# DDR32SS0_CTLPHY_WRAP_CTL_CFG_CTLCFG register map
Vendor: Texas Instruments
Registers are 32-bit, read-write, reset 0x0 unless marked. A register's access mark holds for its fields unless they carry their own. Offsets are as the file gives them; [hi:lo] are bit positions; {n}, {i} and the like mark numbered series.

## DDR32SS0_CTLPHY_WRAP_CTL_CFG_CTLCFG (part 10 of 11)
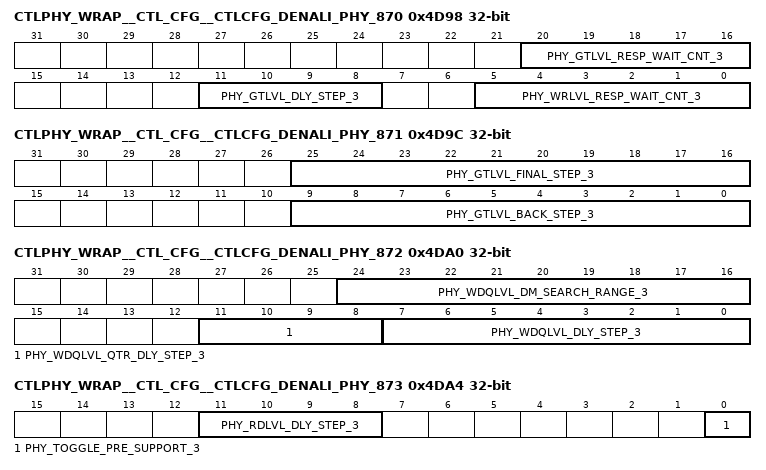
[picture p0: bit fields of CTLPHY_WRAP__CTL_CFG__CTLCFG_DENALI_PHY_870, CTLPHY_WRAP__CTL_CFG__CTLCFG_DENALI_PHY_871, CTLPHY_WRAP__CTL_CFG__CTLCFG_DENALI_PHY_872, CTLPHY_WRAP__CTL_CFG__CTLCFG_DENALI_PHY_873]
0x4D98 CTLPHY_WRAP__CTL_CFG__CTLCFG_DENALI_PHY_870
  [20:16] PHY_GTLVL_RESP_WAIT_CNT_3 — Number of cycles + 4 to wait between dfi_rddata_en and the sampling of the DQS during gate training for slice 3. The valid range is 0x0 to 0xB.
  [11:8] PHY_GTLVL_DLY_STEP_3 — DQS target delay step size during gate training for slice 3.
  [5:0] PHY_WRLVL_RESP_WAIT_CNT_3 — Number of cycles to wait between dfi_wrlvl_strobe and the sampling of the DQs during write leveling for slice 3.
0x4D9C CTLPHY_WRAP__CTL_CFG__CTLCFG_DENALI_PHY_871
  [25:16] PHY_GTLVL_FINAL_STEP_3 — Final backup step delay used in gate training algorithm for slice 3.
  [9:0] PHY_GTLVL_BACK_STEP_3 — Interim backup step delay used in gate training algorithm for slice 3.
0x4DA0 CTLPHY_WRAP__CTL_CFG__CTLCFG_DENALI_PHY_872
  [24:16] PHY_WDQLVL_DM_SEARCH_RANGE_3 — The dm target delay search range for non-lpddr4 DM training for slice 3.
  [11:8] PHY_WDQLVL_QTR_DLY_STEP_3 — Defines the step granularity for the logic to use once an edge is found for slice 3. When this occurs, the logic jumps back to the previous invalid value and uses this step size to determine a more accurate delay value.
  [7:0] PHY_WDQLVL_DLY_STEP_3 — DQ target delay step size during write data leveling for slice 3.
0x4DA4 CTLPHY_WRAP__CTL_CFG__CTLCFG_DENALI_PHY_873
  [11:8] PHY_RDLVL_DLY_STEP_3 — DQS target delay step size during read leveling for slice 3.
  [0] PHY_TOGGLE_PRE_SUPPORT_3 — Support the toggle read preamble for LPDDR4 for slice 3.
0x4DA8 CTLPHY_WRAP__CTL_CFG__CTLCFG_DENALI_PHY_874
  [9:0] PHY_RDLVL_MAX_EDGE_3 — The maximun rdlvl target delay search window for read eye training for slice 3.
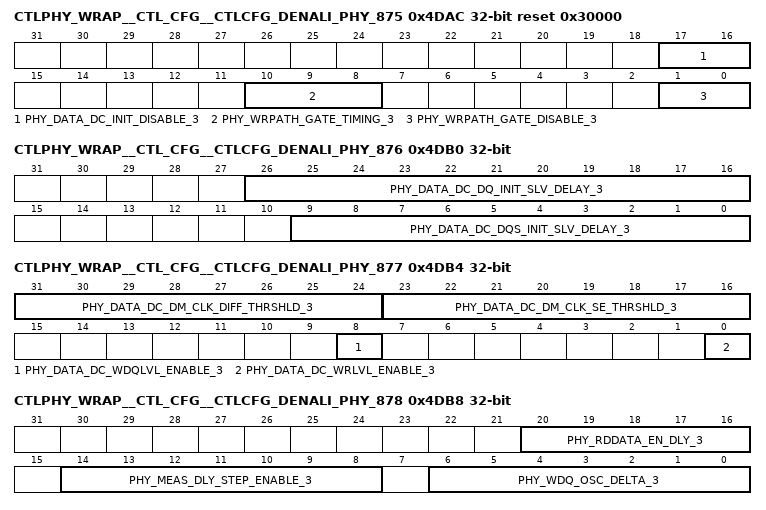
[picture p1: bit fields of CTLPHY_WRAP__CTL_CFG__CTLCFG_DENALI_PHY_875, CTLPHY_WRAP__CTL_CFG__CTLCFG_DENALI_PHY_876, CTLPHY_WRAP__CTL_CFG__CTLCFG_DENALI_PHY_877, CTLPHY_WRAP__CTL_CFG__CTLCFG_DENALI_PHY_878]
0x4DAC CTLPHY_WRAP__CTL_CFG__CTLCFG_DENALI_PHY_875 reset 0x30000
  [17:16] PHY_DATA_DC_INIT_DISABLE_3 — Disable duty cycle adjust at initialization for slice 3.
  [10:8] PHY_WRPATH_GATE_TIMING_3 — Write path clock gating timing for slice 3. it means additional clock number to write path clock gate
  [1:0] PHY_WRPATH_GATE_DISABLE_3 — Write path clock gating disable for slice 3. [0]: disable pull in wrdata_en; [1]: disable write path clock gating, clock always on
0x4DB0 CTLPHY_WRAP__CTL_CFG__CTLCFG_DENALI_PHY_876
  [26:16] PHY_DATA_DC_DQ_INIT_SLV_DELAY_3 — Initial value of write DQ target delay for slice 3.
  [9:0] PHY_DATA_DC_DQS_INIT_SLV_DELAY_3 — Initial value of write DQS target delay for slice 3.
0x4DB4 CTLPHY_WRAP__CTL_CFG__CTLCFG_DENALI_PHY_877
  [31:24] PHY_DATA_DC_DM_CLK_DIFF_THRSHLD_3 — Clock measurement cell threshold offset for differential signals for slice 3.
  [23:16] PHY_DATA_DC_DM_CLK_SE_THRSHLD_3 — Clock measurement cell threshold offset for single ended signals for slice 3.
  [8] PHY_DATA_DC_WDQLVL_ENABLE_3 — Enable duty cycle adjust during write DQ training for slice 3.
  [0] PHY_DATA_DC_WRLVL_ENABLE_3 — Enable duty cycle adjust during write leveling for slice 3.
0x4DB8 CTLPHY_WRAP__CTL_CFG__CTLCFG_DENALI_PHY_878
  [20:16] PHY_RDDATA_EN_DLY_3 — Number of cycles that the dfi_rddata_en signal is early for slice 3.
  [14:8] PHY_MEAS_DLY_STEP_ENABLE_3 — Data slice training step definition using phy_meas_dly_step_value for slice 3.
  [6:0] PHY_WDQ_OSC_DELTA_3 — Target delay offset that applies to a 1 bit change of dfi_wdq_osc_code for slice 3.
0x4DBC CTLPHY_WRAP__CTL_CFG__CTLCFG_DENALI_PHY_879
  [31:0] PHY_DQ_DM_SWIZZLE0_3 — DQ/DM bit swizzling 0 for slice 3. Bits [3:0] inform the PHY which bit in {DM,DQ]} map to DQ0, Bits [7:4] inform the PHY which bit in {DM,DQ} map to DQ1, etc.
0x4DC0 CTLPHY_WRAP__CTL_CFG__CTLCFG_DENALI_PHY_880
  [3:0] PHY_DQ_DM_SWIZZLE1_3 — DQ/DM bit swizzling 1 for slice 3. Bits [3:0] inform the PHY which bit in {DM,DQ]} map to DM.
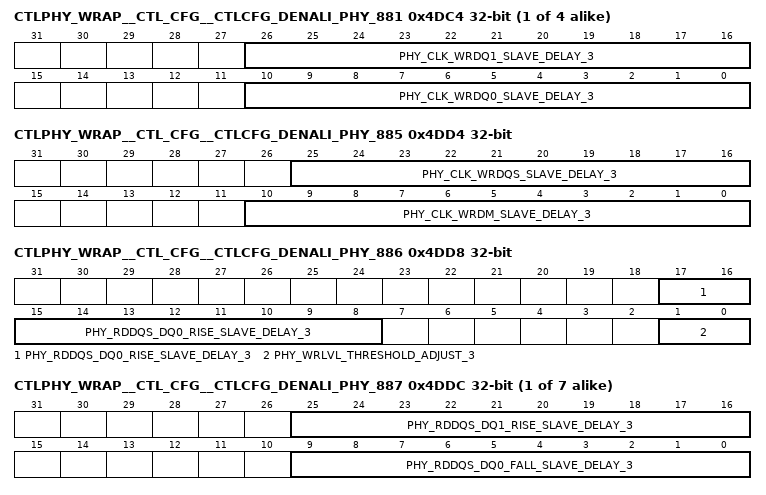
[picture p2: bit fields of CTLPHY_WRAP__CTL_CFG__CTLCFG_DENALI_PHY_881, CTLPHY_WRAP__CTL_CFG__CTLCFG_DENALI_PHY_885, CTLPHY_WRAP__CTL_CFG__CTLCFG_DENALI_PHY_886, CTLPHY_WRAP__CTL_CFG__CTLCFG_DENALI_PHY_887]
{0x4000+4i} CTLPHY_WRAP__CTL_CFG__CTLCFG_DENALI_PHY_{i} (i=881..884)
  [26:16] PHY_CLK_WRDQ{2i-1761}_SLAVE_DELAY_3 — Write clock target delay setting for DQ{2i-1761} for slice 3.
  [10:0] PHY_CLK_WRDQ{2i-1762}_SLAVE_DELAY_3 — Write clock target delay setting for DQ{2i-1762} for slice 3.
0x4DD4 CTLPHY_WRAP__CTL_CFG__CTLCFG_DENALI_PHY_885
  [25:16] PHY_CLK_WRDQS_SLAVE_DELAY_3 — Write clock target delay setting for DQS for slice 3.
  [10:0] PHY_CLK_WRDM_SLAVE_DELAY_3 — Write clock target delay setting for DM for slice 3.
0x4DD8 CTLPHY_WRAP__CTL_CFG__CTLCFG_DENALI_PHY_886
  [17:8] PHY_RDDQS_DQ0_RISE_SLAVE_DELAY_3 — Rising edge read DQS target delay setting for DQ0 for slice 3.
  [1:0] PHY_WRLVL_THRESHOLD_ADJUST_3 — Write level threshold adjust value based on those thresholds for DQS for slice 3.
{0x4000+4i} CTLPHY_WRAP__CTL_CFG__CTLCFG_DENALI_PHY_{i} (i=887..893)
  [25:16] PHY_RDDQS_DQ{i-886}_RISE_SLAVE_DELAY_3 — Rising edge read DQS target delay setting for DQ{i-886} for slice 3.
  [9:0] PHY_RDDQS_DQ{i-887}_FALL_SLAVE_DELAY_3 — Falling edge read DQS target delay setting for DQ{i-887} for slice 3.
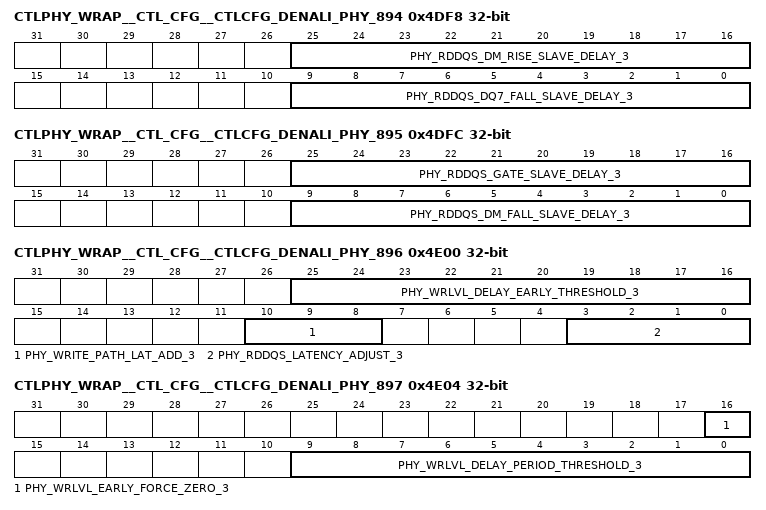
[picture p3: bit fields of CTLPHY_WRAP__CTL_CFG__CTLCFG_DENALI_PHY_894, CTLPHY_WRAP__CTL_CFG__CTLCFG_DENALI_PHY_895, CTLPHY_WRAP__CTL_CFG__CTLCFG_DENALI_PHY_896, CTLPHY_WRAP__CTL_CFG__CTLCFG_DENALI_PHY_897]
0x4DF8 CTLPHY_WRAP__CTL_CFG__CTLCFG_DENALI_PHY_894
  [25:16] PHY_RDDQS_DM_RISE_SLAVE_DELAY_3 — Rising edge read DQS target delay setting for DM for slice 3.
  [9:0] PHY_RDDQS_DQ7_FALL_SLAVE_DELAY_3 — Falling edge read DQS target delay setting for DQ7 for slice 3.
0x4DFC CTLPHY_WRAP__CTL_CFG__CTLCFG_DENALI_PHY_895
  [25:16] PHY_RDDQS_GATE_SLAVE_DELAY_3 — Read DQS target delay setting for slice 3.
  [9:0] PHY_RDDQS_DM_FALL_SLAVE_DELAY_3 — Falling edge read DQS target delay setting for DM for slice 3.
0x4E00 CTLPHY_WRAP__CTL_CFG__CTLCFG_DENALI_PHY_896
  [25:16] PHY_WRLVL_DELAY_EARLY_THRESHOLD_3 — Write level delay threshold above which will be considered in previous cycle for slice 3.
  [10:8] PHY_WRITE_PATH_LAT_ADD_3 — Number of cycles to delay the incoming dfi_wrdata_en/dfi_wrdata signals for slice 3.
  [3:0] PHY_RDDQS_LATENCY_ADJUST_3 — Number of cycles to delay the incoming dfi_rddata_en for read DQS gate generation for slice 3.
0x4E04 CTLPHY_WRAP__CTL_CFG__CTLCFG_DENALI_PHY_897
  [16] PHY_WRLVL_EARLY_FORCE_ZERO_3 — Force the final write level delay value [that meets the early threshold] to 0 for slice 3.
  [9:0] PHY_WRLVL_DELAY_PERIOD_THRESHOLD_3 — Write level delay threshold below which will add a cycle of write path latency for slice 3.
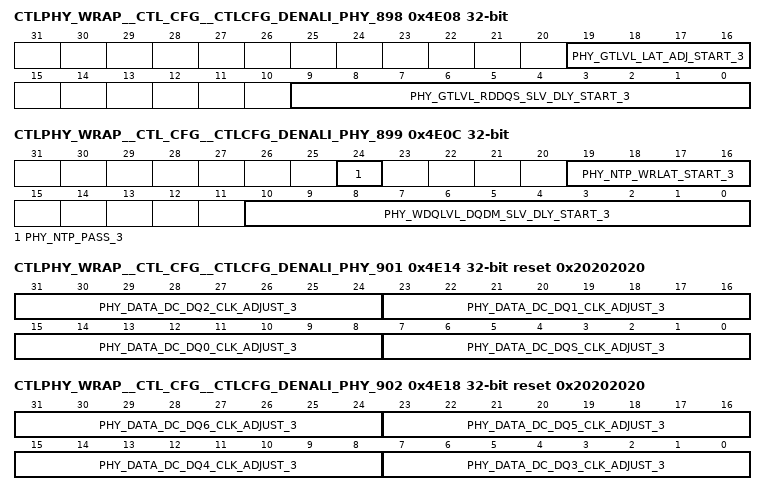
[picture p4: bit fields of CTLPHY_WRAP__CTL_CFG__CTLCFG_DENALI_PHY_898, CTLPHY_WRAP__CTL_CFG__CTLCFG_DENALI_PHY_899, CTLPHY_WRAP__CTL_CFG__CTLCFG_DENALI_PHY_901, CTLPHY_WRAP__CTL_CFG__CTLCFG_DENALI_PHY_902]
0x4E08 CTLPHY_WRAP__CTL_CFG__CTLCFG_DENALI_PHY_898
  [19:16] PHY_GTLVL_LAT_ADJ_START_3 — Initial read DQS gate cycle delay from dfi_rddata_en during gate training for slice 3.
  [9:0] PHY_GTLVL_RDDQS_SLV_DLY_START_3 — Initial read DQS gate target delay setting during gate training for slice 3.
0x4E0C CTLPHY_WRAP__CTL_CFG__CTLCFG_DENALI_PHY_899
  [24] PHY_NTP_PASS_3 — Indicates if No-topology training found a passing result for slice 3.
  [19:16] PHY_NTP_WRLAT_START_3 — Initial value for phy_write_path_lat_add for No-topology training and early threshold for slice 3.
  [10:0] PHY_WDQLVL_DQDM_SLV_DLY_START_3 — Initial DQ/DM target delay setting during write data leveling for slice 3.
0x4E10 CTLPHY_WRAP__CTL_CFG__CTLCFG_DENALI_PHY_900
  [9:0] PHY_RDLVL_RDDQS_DQ_SLV_DLY_START_3 — Read leveling starting value for the DQS/DQ target delay settings for slice 3.
0x4E14 CTLPHY_WRAP__CTL_CFG__CTLCFG_DENALI_PHY_901 reset 0x20202020
  [31:24] PHY_DATA_DC_DQ2_CLK_ADJUST_3 — Adjust value of Duty Cycle Adjuster for slice 3.
  [23:16] PHY_DATA_DC_DQ1_CLK_ADJUST_3 — Adjust value of Duty Cycle Adjuster for slice 3.
  [15:8] PHY_DATA_DC_DQ0_CLK_ADJUST_3 — Adjust value of Duty Cycle Adjuster for slice 3.
  [7:0] PHY_DATA_DC_DQS_CLK_ADJUST_3 — Adjust value of Duty Cycle Adjuster for slice 3.
0x4E18 CTLPHY_WRAP__CTL_CFG__CTLCFG_DENALI_PHY_902 reset 0x20202020
  [8n-17:8n-24] PHY_DATA_DC_DQ{n}_CLK_ADJUST_3 (n=3..6) — Adjust value of Duty Cycle Adjuster for slice 3.
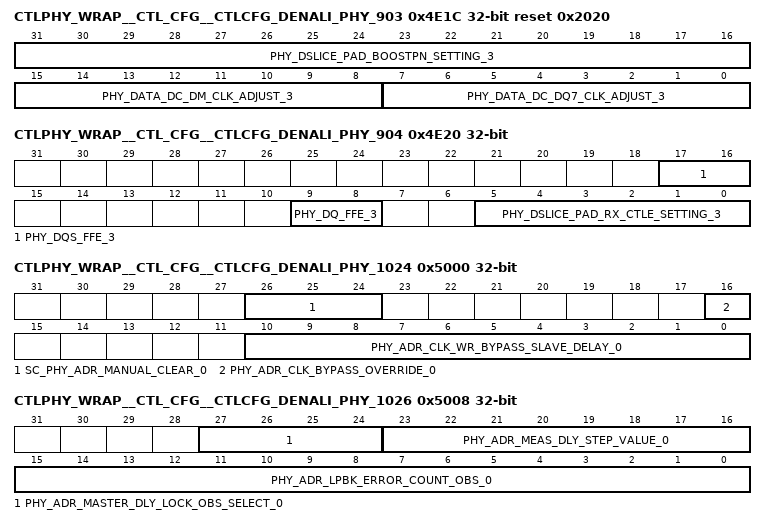
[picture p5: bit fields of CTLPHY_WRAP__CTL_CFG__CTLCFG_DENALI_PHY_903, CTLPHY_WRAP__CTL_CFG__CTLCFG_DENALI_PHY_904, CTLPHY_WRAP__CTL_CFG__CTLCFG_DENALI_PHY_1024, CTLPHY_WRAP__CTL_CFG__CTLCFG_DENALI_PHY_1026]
0x4E1C CTLPHY_WRAP__CTL_CFG__CTLCFG_DENALI_PHY_903 reset 0x2020
  [31:16] PHY_DSLICE_PAD_BOOSTPN_SETTING_3 — Setting for boost P/N of pad for slice 3.
  [15:8] PHY_DATA_DC_DM_CLK_ADJUST_3 — Adjust value of Duty Cycle Adjuster for slice 3.
  [7:0] PHY_DATA_DC_DQ7_CLK_ADJUST_3 — Adjust value of Duty Cycle Adjuster for slice 3.
0x4E20 CTLPHY_WRAP__CTL_CFG__CTLCFG_DENALI_PHY_904
  [17:16] PHY_DQS_FFE_3 — TX_FFE setting for DQS pad for slice 3.
  [9:8] PHY_DQ_FFE_3 — TX_FFE setting for DQ/DM pad for slice 3.
  [5:0] PHY_DSLICE_PAD_RX_CTLE_SETTING_3 — Setting for RX ctle P/N of pad for slice 3.
0x5000 CTLPHY_WRAP__CTL_CFG__CTLCFG_DENALI_PHY_1024 access per field
  [26:24] SC_PHY_ADR_MANUAL_CLEAR_0 wo — Manual reset/clear of internal logic for address slice 0. Bit [0] is reset of controller delay min/max lock values. Bit [1] is manual reset of controller delay unlock counter. Bit [2] clears the loopback error/results registers. Set each bit to 1 to reset. WRITE-ONLY
  [16] PHY_ADR_CLK_BYPASS_OVERRIDE_0 rw — Bypass mode override setting for address slice 0. Set to 1 to enable.
  [10:0] PHY_ADR_CLK_WR_BYPASS_SLAVE_DELAY_0 rw — Command/Address clock bypass mode target delay setting for address slice 0.
0x5004 CTLPHY_WRAP__CTL_CFG__CTLCFG_DENALI_PHY_1025 ro reset 0x1000
  [31:0] PHY_ADR_LPBK_RESULT_OBS_0 — Observation register containing loopback status/results for address slice 0. READ-ONLY
0x5008 CTLPHY_WRAP__CTL_CFG__CTLCFG_DENALI_PHY_1026 access per field
  [27:24] PHY_ADR_MASTER_DLY_LOCK_OBS_SELECT_0 rw — Select value to map the internal controller delay observation registers to the accessible controller delay observation register for address slice 0.
  [23:16] PHY_ADR_MEAS_DLY_STEP_VALUE_0 ro — Contains the fraction of a cycle in 1 delay element numerator with demominator of 512, for address slice 0. READ-ONLY
  [15:0] PHY_ADR_LPBK_ERROR_COUNT_OBS_0 ro — Observation register containing total number of loopback error data for address slice 0. READ-ONLY
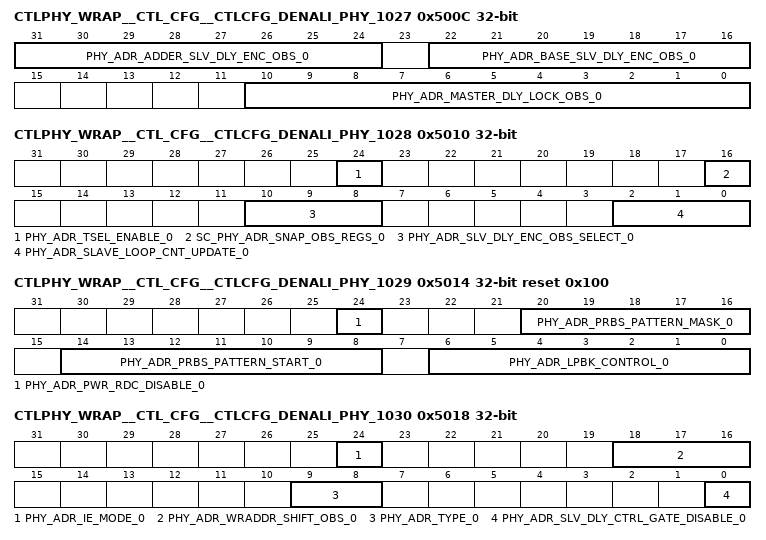
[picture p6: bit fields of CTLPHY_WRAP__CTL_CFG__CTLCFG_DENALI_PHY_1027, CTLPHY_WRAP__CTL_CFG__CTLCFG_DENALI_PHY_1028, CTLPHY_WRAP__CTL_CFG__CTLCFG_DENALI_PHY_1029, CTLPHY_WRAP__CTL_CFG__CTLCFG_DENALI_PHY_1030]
0x500C CTLPHY_WRAP__CTL_CFG__CTLCFG_DENALI_PHY_1027 ro
  [31:24] PHY_ADR_ADDER_SLV_DLY_ENC_OBS_0 — Observation register containing addr target delay for address slice 0. READ-ONLY
  [22:16] PHY_ADR_BASE_SLV_DLY_ENC_OBS_0 — Observation register containing base target delay for address slice 0. READ-ONLY
  [10:0] PHY_ADR_MASTER_DLY_LOCK_OBS_0 — Observation register containing controller delay results for address slice 0. READ-ONLY
0x5010 CTLPHY_WRAP__CTL_CFG__CTLCFG_DENALI_PHY_1028 access per field
  [24] PHY_ADR_TSEL_ENABLE_0 rw — Enables tsel_en for address slice 0.
  [16] SC_PHY_ADR_SNAP_OBS_REGS_0 wo — Initiates a snapshot of the internal observation registers for address slice 0. Set to 1 to trigger. WRITE-ONLY
  [10:8] PHY_ADR_SLV_DLY_ENC_OBS_SELECT_0 rw — Select value to map the addr bits delay observation registers to the accessible delay observation register for address slice 0.
  [2:0] PHY_ADR_SLAVE_LOOP_CNT_UPDATE_0 rw — Reserved for address slice 0.
0x5014 CTLPHY_WRAP__CTL_CFG__CTLCFG_DENALI_PHY_1029 reset 0x100
  [24] PHY_ADR_PWR_RDC_DISABLE_0 — Power reduction disable for address slice 0.
  [20:16] PHY_ADR_PRBS_PATTERN_MASK_0 — PRBS7 mask signal for address slice 0.
  [14:8] PHY_ADR_PRBS_PATTERN_START_0 — PRBS7 start pattern for address slice 0.
  [6:0] PHY_ADR_LPBK_CONTROL_0 — Loopback control bits for address slice 0.
0x5018 CTLPHY_WRAP__CTL_CFG__CTLCFG_DENALI_PHY_1030 access per field
  [24] PHY_ADR_IE_MODE_0 rw — Input enable control for address slice 0.
  [18:16] PHY_ADR_WRADDR_SHIFT_OBS_0 ro — Observation register containing automatic half cycle and cycle shift values for address slice 0. READ-ONLY
  [9:8] PHY_ADR_TYPE_0 rw — DRAM type for address slice 0.
  [0] PHY_ADR_SLV_DLY_CTRL_GATE_DISABLE_0 rw — Power reduction slv_dly_control block gate disable for address slice 0.
0x501C CTLPHY_WRAP__CTL_CFG__CTLCFG_DENALI_PHY_1031
  [26:0] PHY_ADR_DDL_MODE_0 — DDL mode for address slice 0.
0x5020 CTLPHY_WRAP__CTL_CFG__CTLCFG_DENALI_PHY_1032
  [5:0] PHY_ADR_DDL_MASK_0 — DDL mask for address slice 0.
0x5024 CTLPHY_WRAP__CTL_CFG__CTLCFG_DENALI_PHY_1033 ro
  [31:0] PHY_ADR_DDL_TEST_OBS_0 — Observation register containing DDL test bits for address slice 0. READ-ONLY
0x5028 CTLPHY_WRAP__CTL_CFG__CTLCFG_DENALI_PHY_1034 ro
  [31:0] PHY_ADR_DDL_TEST_MSTR_DLY_OBS_0 — Observation register containing controller DDL bits for address slice 0. READ-ONLY
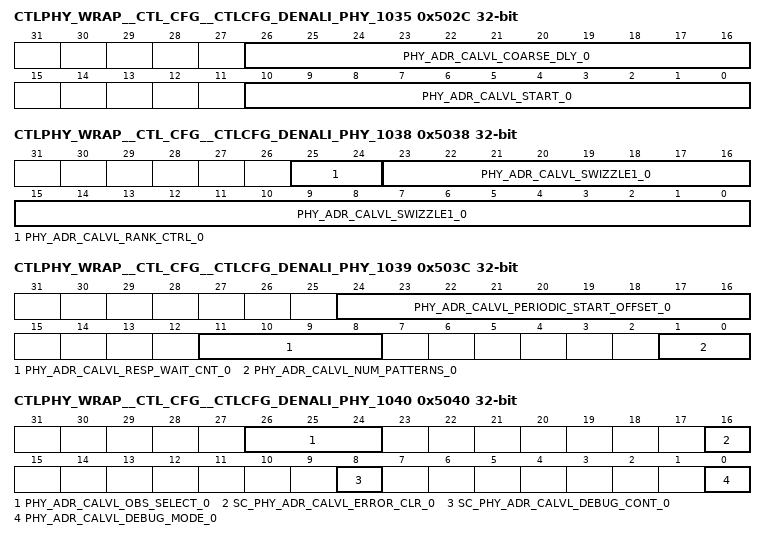
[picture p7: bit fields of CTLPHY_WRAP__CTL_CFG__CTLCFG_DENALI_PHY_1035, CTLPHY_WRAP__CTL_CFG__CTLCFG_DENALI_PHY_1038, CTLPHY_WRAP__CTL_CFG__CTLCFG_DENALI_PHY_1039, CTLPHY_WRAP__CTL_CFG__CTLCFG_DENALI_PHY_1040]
0x502C CTLPHY_WRAP__CTL_CFG__CTLCFG_DENALI_PHY_1035
  [26:16] PHY_ADR_CALVL_COARSE_DLY_0 — Coarse CA training DDL increment value for address slice 0.
  [10:0] PHY_ADR_CALVL_START_0 — CA training DDL start value for address slice 0.
0x5030 CTLPHY_WRAP__CTL_CFG__CTLCFG_DENALI_PHY_1036
  [10:0] PHY_ADR_CALVL_QTR_0 — CA training DDL quarter cycle delay value for address slice 0.
0x5034 CTLPHY_WRAP__CTL_CFG__CTLCFG_DENALI_PHY_1037
  [23:0] PHY_ADR_CALVL_SWIZZLE0_0 — CA training RD DQ bit swizzle map 0 for address slice 0.
0x5038 CTLPHY_WRAP__CTL_CFG__CTLCFG_DENALI_PHY_1038
  [25:24] PHY_ADR_CALVL_RANK_CTRL_0 — CA training rank aggregation control bits for address slice 0.
  [23:0] PHY_ADR_CALVL_SWIZZLE1_0 — CA training RD DQ bit swizzle map 1 for address slice 0.
0x503C CTLPHY_WRAP__CTL_CFG__CTLCFG_DENALI_PHY_1039
  [24:16] PHY_ADR_CALVL_PERIODIC_START_OFFSET_0 — Relative offset to start periodic CALVL from previous result
  [11:8] PHY_ADR_CALVL_RESP_WAIT_CNT_0 — Number of samples to wait before sampling response during CA training for address slice 0.
  [1:0] PHY_ADR_CALVL_NUM_PATTERNS_0 — Number of patterns to use during CA training for address slice 0.
0x5040 CTLPHY_WRAP__CTL_CFG__CTLCFG_DENALI_PHY_1040 access per field
  [26:24] PHY_ADR_CALVL_OBS_SELECT_0 rw — CA bit lane to observe result from OBS0 during CA training for address slice 0.
  [16] SC_PHY_ADR_CALVL_ERROR_CLR_0 wo — Clears the CA training state machine error status for address slice 0. Set to 1 to trigger. WRITE-ONLY
  [8] SC_PHY_ADR_CALVL_DEBUG_CONT_0 wo — Allows the CA training state machine to advance [when in debug mode] for address slice 0. Set to 1 to trigger. WRITE-ONLY
  [0] PHY_ADR_CALVL_DEBUG_MODE_0 rw — Enables CA training debug mode for address slice 0. Set to 1 to enable.
0x5044 CTLPHY_WRAP__CTL_CFG__CTLCFG_DENALI_PHY_1041 ro
  [31:0] PHY_ADR_CALVL_CH0_OBS0_0 — Observation register for CA training for channel 0 slice 0. READ-ONLY
0x5048 CTLPHY_WRAP__CTL_CFG__CTLCFG_DENALI_PHY_1042 ro
  [31:0] PHY_ADR_CALVL_CH1_OBS0_0 — Observation register for CA training for channel 1 slice 0. READ-ONLY
0x504C CTLPHY_WRAP__CTL_CFG__CTLCFG_DENALI_PHY_1043 ro
  [31:0] PHY_ADR_CALVL_OBS1_0 — Observation register contains general CA training bits for slice 0. READ-ONLY
0x5050 CTLPHY_WRAP__CTL_CFG__CTLCFG_DENALI_PHY_1044 ro reset 0x100
  [31:0] PHY_ADR_CALVL_OBS2_0 — Observation register contains periodic CA training bits for slice 0. READ-ONLY
0x5054 CTLPHY_WRAP__CTL_CFG__CTLCFG_DENALI_PHY_1045
  [19:0] PHY_ADR_CALVL_FG_0_0 — CA training foreground pattern 0 for address slice 0.
0x5058 CTLPHY_WRAP__CTL_CFG__CTLCFG_DENALI_PHY_1046
  [19:0] PHY_ADR_CALVL_BG_0_0 — CA training background pattern 0 for address slice 0.
0x505C CTLPHY_WRAP__CTL_CFG__CTLCFG_DENALI_PHY_1047
  [19:0] PHY_ADR_CALVL_FG_1_0 — CA training foreground pattern 1 for address slice 0.
0x5060 CTLPHY_WRAP__CTL_CFG__CTLCFG_DENALI_PHY_1048
  [19:0] PHY_ADR_CALVL_BG_1_0 — CA training background pattern 1 for address slice 0.
0x5064 CTLPHY_WRAP__CTL_CFG__CTLCFG_DENALI_PHY_1049
  [19:0] PHY_ADR_CALVL_FG_2_0 — CA training foreground pattern 2 for address slice 0.
0x5068 CTLPHY_WRAP__CTL_CFG__CTLCFG_DENALI_PHY_1050
  [19:0] PHY_ADR_CALVL_BG_2_0 — CA training background pattern 2 for address slice 0.
0x506C CTLPHY_WRAP__CTL_CFG__CTLCFG_DENALI_PHY_1051
  [19:0] PHY_ADR_CALVL_FG_3_0 — CA training foreground pattern 3 for address slice 0.
0x5070 CTLPHY_WRAP__CTL_CFG__CTLCFG_DENALI_PHY_1052
  [19:0] PHY_ADR_CALVL_BG_3_0 — CA training background pattern 3 for address slice 0.
0x5074 CTLPHY_WRAP__CTL_CFG__CTLCFG_DENALI_PHY_1053
  [29:0] PHY_ADR_ADDR_SEL_0 — Selects which DFI address pins connect to which CA pins for LPDDR3/4 for address slice 0.
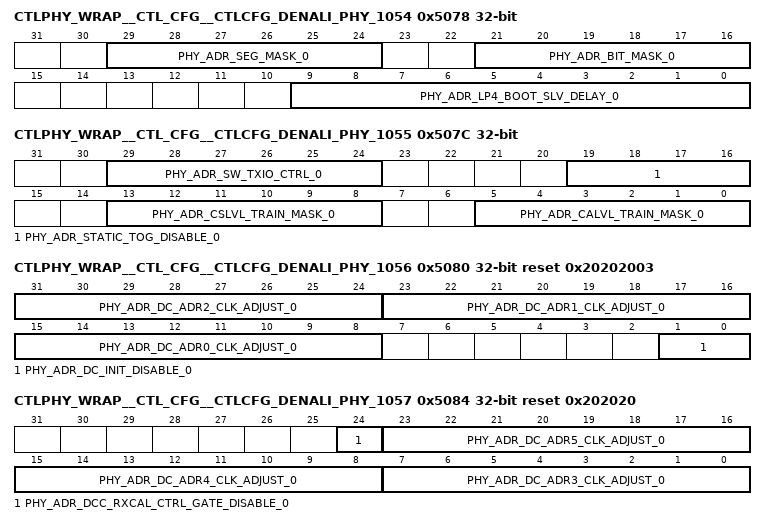
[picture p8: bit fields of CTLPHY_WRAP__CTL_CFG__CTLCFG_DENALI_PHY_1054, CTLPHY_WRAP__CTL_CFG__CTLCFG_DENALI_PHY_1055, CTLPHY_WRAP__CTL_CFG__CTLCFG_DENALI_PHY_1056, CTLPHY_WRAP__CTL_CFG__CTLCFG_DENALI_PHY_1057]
0x5078 CTLPHY_WRAP__CTL_CFG__CTLCFG_DENALI_PHY_1054
  [29:24] PHY_ADR_SEG_MASK_0 — Segment mask bit for address slice 0. Set to 1 to indicate that the bit is either CA 4 or CA 9.
  [21:16] PHY_ADR_BIT_MASK_0 — Mask bit for address slice 0. Set to 1 to indicate that the bit is used.
  [9:0] PHY_ADR_LP4_BOOT_SLV_DELAY_0 — Address target delay setting during the LPDDR4 boot frequency operation for address slice 0.
0x507C CTLPHY_WRAP__CTL_CFG__CTLCFG_DENALI_PHY_1055
  [29:24] PHY_ADR_SW_TXIO_CTRL_0 — Controls address pad output enable for address slice 0. Set to 1 to disable output enable.
  [19:16] PHY_ADR_STATIC_TOG_DISABLE_0 — Toggle control during static activity for address slice 0. Set bit to dsiable toggling, bit0: Write path delay line, bit1: Read path delay line, bit2: Read data path, bit3: clk_phy, bit4: controller delay line.
  [13:8] PHY_ADR_CSLVL_TRAIN_MASK_0 — Mask bit for CS training participation for address slice 0. Set to 1 to indicate that the bit is participating in CS training.
  [5:0] PHY_ADR_CALVL_TRAIN_MASK_0 — Mask bit for CA training participation for address slice 0. Set to 1 to indicate that the bit is participating in CA training.
0x5080 CTLPHY_WRAP__CTL_CFG__CTLCFG_DENALI_PHY_1056 reset 0x20202003
  [31:24] PHY_ADR_DC_ADR2_CLK_ADJUST_0 — Adjust value of Clock Duty Cycle Adjuster lane 2 for address slice 0.
  [23:16] PHY_ADR_DC_ADR1_CLK_ADJUST_0 — Adjust value of Clock Duty Cycle Adjuster lane 1 for address slice 0.
  [15:8] PHY_ADR_DC_ADR0_CLK_ADJUST_0 — Adjust value of Clock Duty Cycle Adjuster lane 0 for address slice 0.
  [1:0] PHY_ADR_DC_INIT_DISABLE_0 — Duty Cycle Corrector disable at initialization for address slice 0. Set to 1 to disable, bit [1] controls data path, bit [0] controls clock path.
0x5084 CTLPHY_WRAP__CTL_CFG__CTLCFG_DENALI_PHY_1057 reset 0x202020
  [24] PHY_ADR_DCC_RXCAL_CTRL_GATE_DISABLE_0 — DCC and RX_CAL clk gate disable for address slice 0. 1 = disable clk gate.
  [23:16] PHY_ADR_DC_ADR5_CLK_ADJUST_0 — Adjust value of Clock Duty Cycle Adjuster lane 5 for address slice 0.
  [15:8] PHY_ADR_DC_ADR4_CLK_ADJUST_0 — Adjust value of Clock Duty Cycle Adjuster lane 4 for address slice 0.
  [7:0] PHY_ADR_DC_ADR3_CLK_ADJUST_0 — Adjust value of Clock Duty Cycle Adjuster lane 3 for address slice 0.
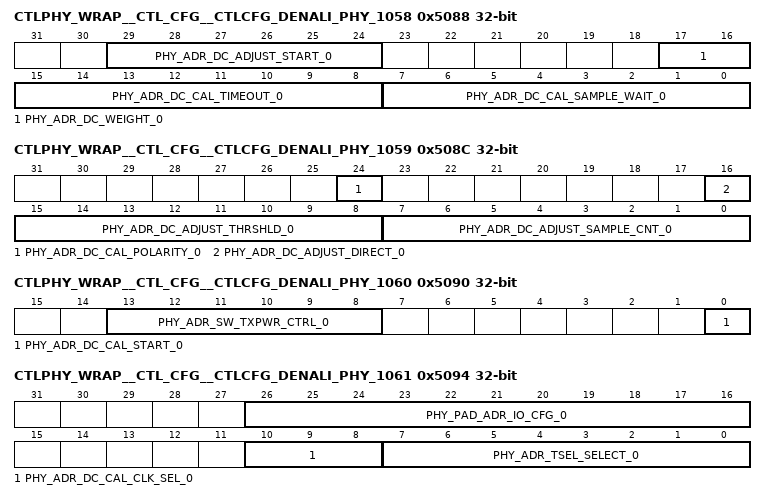
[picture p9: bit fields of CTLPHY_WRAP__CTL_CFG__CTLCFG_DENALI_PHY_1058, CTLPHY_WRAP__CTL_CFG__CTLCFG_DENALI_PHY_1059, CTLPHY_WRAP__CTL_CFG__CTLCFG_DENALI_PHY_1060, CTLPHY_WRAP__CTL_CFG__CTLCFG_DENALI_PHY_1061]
0x5088 CTLPHY_WRAP__CTL_CFG__CTLCFG_DENALI_PHY_1058
  [29:24] PHY_ADR_DC_ADJUST_START_0 — DCC calibration starting value for address slice 0.
  [17:16] PHY_ADR_DC_WEIGHT_0 — DCC weighting factor base value for address slice 0.
  [15:8] PHY_ADR_DC_CAL_TIMEOUT_0 — DCC number of iterations to wait before timeout for address slice 0.
  [7:0] PHY_ADR_DC_CAL_SAMPLE_WAIT_0 — DCC cycles to wait after calibration change before sampling results for address slice 0.
0x508C CTLPHY_WRAP__CTL_CFG__CTLCFG_DENALI_PHY_1059
  [24] PHY_ADR_DC_CAL_POLARITY_0 — DCC calibration polarity for address slice 0.
  [16] PHY_ADR_DC_ADJUST_DIRECT_0 — DCC adjust direction for address slice 0.
  [15:8] PHY_ADR_DC_ADJUST_THRSHLD_0 — DCC adjust threshold around the mid-point for address slice 0.
  [7:0] PHY_ADR_DC_ADJUST_SAMPLE_CNT_0 — DCC number of samples to take for address slice 0.
0x5090 CTLPHY_WRAP__CTL_CFG__CTLCFG_DENALI_PHY_1060
  [13:8] PHY_ADR_SW_TXPWR_CTRL_0 — Disable address output enables in deep sleep mode for address slice 0.
  [0] PHY_ADR_DC_CAL_START_0 — DCC Manual trigger for address slice 0.
0x5094 CTLPHY_WRAP__CTL_CFG__CTLCFG_DENALI_PHY_1061
  [26:16] PHY_PAD_ADR_IO_CFG_0 — Controls I/O pads for address pad for address slice 0. Bits [10:5] = Park value, bits [4] park override, bits [2:0] clk divider.
  [10:8] PHY_ADR_DC_CAL_CLK_SEL_0 — DCC CAL clock for address slice 0.
  [7:0] PHY_ADR_TSEL_SELECT_0 — Tsel select values for address slice 0.
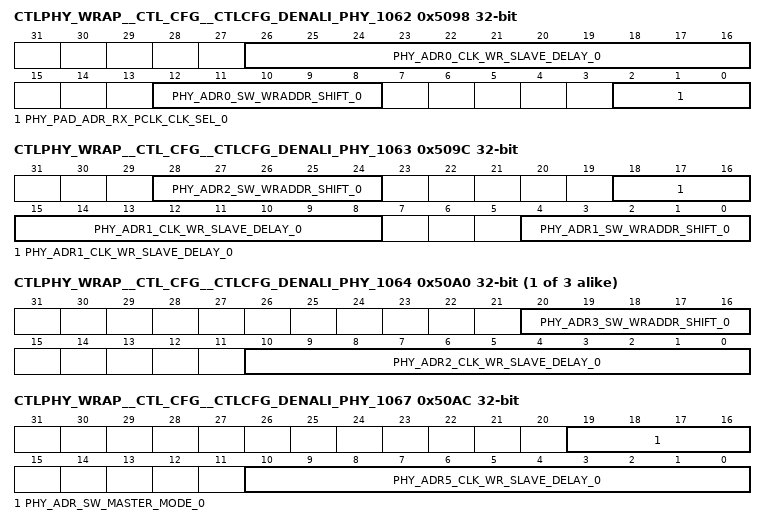
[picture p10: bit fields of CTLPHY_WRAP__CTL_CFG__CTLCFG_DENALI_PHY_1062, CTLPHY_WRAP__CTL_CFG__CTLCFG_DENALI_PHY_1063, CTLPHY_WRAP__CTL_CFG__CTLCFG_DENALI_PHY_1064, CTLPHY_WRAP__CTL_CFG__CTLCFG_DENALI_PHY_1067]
0x5098 CTLPHY_WRAP__CTL_CFG__CTLCFG_DENALI_PHY_1062
  [26:16] PHY_ADR0_CLK_WR_SLAVE_DELAY_0 — CA bit 0 target delay setting for address slice 0.
  [12:8] PHY_ADR0_SW_WRADDR_SHIFT_0 — Manual override of CA bit 0 of automatic half_cycle_shift/cycle_shift for address slice 0. Bit [0] enables override of half_cycle_shift. Bit [1] is the half_cycle_shift value. Bit [2] enables override of cycle shift. Bits [4:3] is the cycle_shift value. For bits [4:3], clear to 0x0 for no offset, program to 0x1 for -1 cycle, program to 0x2 for +1 cycle, or program to 0x3 for -2 cycles.
  [2:0] PHY_PAD_ADR_RX_PCLK_CLK_SEL_0 — Reserved for address slice 0.
0x509C CTLPHY_WRAP__CTL_CFG__CTLCFG_DENALI_PHY_1063
  [28:24] PHY_ADR2_SW_WRADDR_SHIFT_0 — Manual override of CA bit 2 of automatic half_cycle_shift/cycle_shift for address slice 0. Bit [0] enables override of half_cycle_shift. Bit [1] is the half_cycle_shift value. Bit [2] enables override of cycle shift. Bits [4:3] is the cycle_shift value. For bits [4:3], clear to 0x0 for no offset, program to 0x1 for -1 cycle, program to 0x2 for +1 cycle, or program to 0x3 for -2 cycles.
  [18:8] PHY_ADR1_CLK_WR_SLAVE_DELAY_0 — CA bit 1 target delay setting for address slice 0.
  [4:0] PHY_ADR1_SW_WRADDR_SHIFT_0 — Manual override of CA bit 1 of automatic half_cycle_shift/cycle_shift for address slice 0. Bit [0] enables override of half_cycle_shift. Bit [1] is the half_cycle_shift value. Bit [2] enables override of cycle shift. Bits [4:3] is the cycle_shift value. For bits [4:3], clear to 0x0 for no offset, program to 0x1 for -1 cycle, program to 0x2 for +1 cycle, or program to 0x3 for -2 cycles.
{0x4000+4i} CTLPHY_WRAP__CTL_CFG__CTLCFG_DENALI_PHY_{i} (i=1064..1066)
  [20:16] PHY_ADR{i-1061}_SW_WRADDR_SHIFT_0 — Manual override of CA bit {i-1061} of automatic half_cycle_shift/cycle_shift for address slice 0. Bit [0] enables override of half_cycle_shift. Bit [1] is the half_cycle_shift value. Bit [2] enables override of cycle shift. Bits [4:3] is the cycle_shift value. For bits [4:3], clear to 0x0 for no offset, program to 0x1 for -1 cycle, program to 0x2 for +1 cycle, or program to 0x3 for -2 cycles.
  [10:0] PHY_ADR{i-1062}_CLK_WR_SLAVE_DELAY_0 — CA bit {i-1062} target delay setting for address slice 0.
0x50AC CTLPHY_WRAP__CTL_CFG__CTLCFG_DENALI_PHY_1067
  [19:16] PHY_ADR_SW_MASTER_MODE_0 — Controller delay line override settings for address slice 0. Bit [0] enables software half clock mode. Bit [1] is the software half clock mode value. Bit [2] enables software bypass mode. Bit [3] is the software bypass mode value.
  [10:0] PHY_ADR5_CLK_WR_SLAVE_DELAY_0 — CA bit 5 target delay setting for address slice 0.
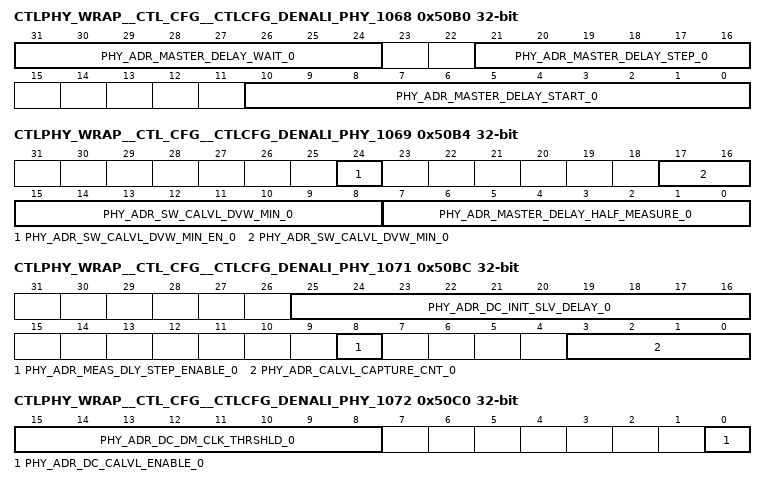
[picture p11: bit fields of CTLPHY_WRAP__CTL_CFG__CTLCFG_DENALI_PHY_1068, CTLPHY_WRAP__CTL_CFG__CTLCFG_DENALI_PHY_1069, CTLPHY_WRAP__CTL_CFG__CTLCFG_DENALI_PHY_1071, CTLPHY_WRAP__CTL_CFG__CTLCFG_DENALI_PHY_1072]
0x50B0 CTLPHY_WRAP__CTL_CFG__CTLCFG_DENALI_PHY_1068
  [31:24] PHY_ADR_MASTER_DELAY_WAIT_0 — Wait cycles for controller delay line locking algorithm for address slice 0. Bits [3:0] is the cycle wait count after a calibration clock setting change. Bits [7:4] is the cycle wait count after a controller delay setting change.
  [21:16] PHY_ADR_MASTER_DELAY_STEP_0 — Incremental step size for controller delay line locking algorithm for address slice 0.
  [10:0] PHY_ADR_MASTER_DELAY_START_0 — Start value for controller delay line locking algorithm for address slice 0.
0x50B4 CTLPHY_WRAP__CTL_CFG__CTLCFG_DENALI_PHY_1069
  [24] PHY_ADR_SW_CALVL_DVW_MIN_EN_0 — Enables the software override data valid window size during CA training for address slice 0.
  [17:8] PHY_ADR_SW_CALVL_DVW_MIN_0 — Sets the software override data valid window size during CA training for address slice 0.
  [7:0] PHY_ADR_MASTER_DELAY_HALF_MEASURE_0 — Defines the number of delay line elements to be considered in determing whether to lock to a half clock cycle for the controller in address slice 0
0x50B8 CTLPHY_WRAP__CTL_CFG__CTLCFG_DENALI_PHY_1070
  [3:0] PHY_ADR_CALVL_DLY_STEP_0 — Sets the delay step size plus 1 during CA training for address slice 0.
0x50BC CTLPHY_WRAP__CTL_CFG__CTLCFG_DENALI_PHY_1071
  [25:16] PHY_ADR_DC_INIT_SLV_DELAY_0 — DCC initialization value of write ADDR target delay for address slice 0.
  [8] PHY_ADR_MEAS_DLY_STEP_ENABLE_0 — Enables delay parameter setting using phy_adr_meas_dly_step_value for address slice 0.
  [3:0] PHY_ADR_CALVL_CAPTURE_CNT_0 — Number of samples to take at each ADDR target delay setting during CA training for address slice 0.
0x50C0 CTLPHY_WRAP__CTL_CFG__CTLCFG_DENALI_PHY_1072
  [15:8] PHY_ADR_DC_DM_CLK_THRSHLD_0 — DCC clock measurement cell threshold offset for address slice 0.
  [0] PHY_ADR_DC_CALVL_ENABLE_0 — DCC enable duty cycle adjust during CA leveling for address slice 0.
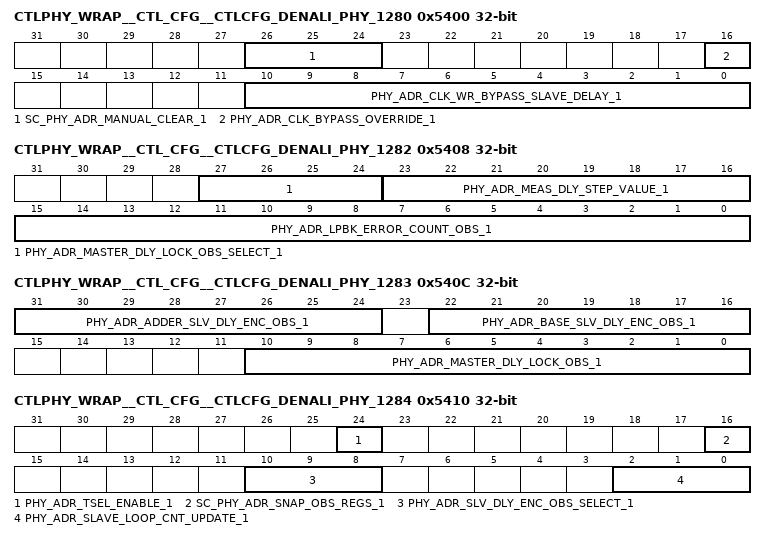
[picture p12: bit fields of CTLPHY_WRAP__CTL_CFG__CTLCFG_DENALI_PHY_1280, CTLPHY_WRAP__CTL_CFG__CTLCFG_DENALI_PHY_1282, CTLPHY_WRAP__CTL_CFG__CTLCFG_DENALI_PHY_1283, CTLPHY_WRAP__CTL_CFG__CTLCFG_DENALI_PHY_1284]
0x5400 CTLPHY_WRAP__CTL_CFG__CTLCFG_DENALI_PHY_1280 access per field
  [26:24] SC_PHY_ADR_MANUAL_CLEAR_1 wo — Manual reset/clear of internal logic for address slice 1. Bit [0] is reset of controller delay min/max lock values. Bit [1] is manual reset of controller delay unlock counter. Bit [2] clears the loopback error/results registers. Set each bit to 1 to reset. WRITE-ONLY
  [16] PHY_ADR_CLK_BYPASS_OVERRIDE_1 rw — Bypass mode override setting for address slice 1. Set to 1 to enable.
  [10:0] PHY_ADR_CLK_WR_BYPASS_SLAVE_DELAY_1 rw — Command/Address clock bypass mode target delay setting for address slice 1.
0x5404 CTLPHY_WRAP__CTL_CFG__CTLCFG_DENALI_PHY_1281 ro reset 0x1000
  [31:0] PHY_ADR_LPBK_RESULT_OBS_1 — Observation register containing loopback status/results for address slice 1. READ-ONLY
0x5408 CTLPHY_WRAP__CTL_CFG__CTLCFG_DENALI_PHY_1282 access per field
  [27:24] PHY_ADR_MASTER_DLY_LOCK_OBS_SELECT_1 rw — Select value to map the internal controller delay observation registers to the accessible controller delay observation register for address slice 1.
  [23:16] PHY_ADR_MEAS_DLY_STEP_VALUE_1 ro — Contains the fraction of a cycle in 1 delay element numerator with demominator of 512, for address slice 1. READ-ONLY
  [15:0] PHY_ADR_LPBK_ERROR_COUNT_OBS_1 ro — Observation register containing total number of loopback error data for address slice 1. READ-ONLY
0x540C CTLPHY_WRAP__CTL_CFG__CTLCFG_DENALI_PHY_1283 ro
  [31:24] PHY_ADR_ADDER_SLV_DLY_ENC_OBS_1 — Observation register containing addr target delay for address slice 1. READ-ONLY
  [22:16] PHY_ADR_BASE_SLV_DLY_ENC_OBS_1 — Observation register containing base target delay for address slice 1. READ-ONLY
  [10:0] PHY_ADR_MASTER_DLY_LOCK_OBS_1 — Observation register containing controller delay results for address slice 1. READ-ONLY
0x5410 CTLPHY_WRAP__CTL_CFG__CTLCFG_DENALI_PHY_1284 access per field
  [24] PHY_ADR_TSEL_ENABLE_1 rw — Enables tsel_en for address slice 1.
  [16] SC_PHY_ADR_SNAP_OBS_REGS_1 wo — Initiates a snapshot of the internal observation registers for address slice 1. Set to 1 to trigger. WRITE-ONLY
  [10:8] PHY_ADR_SLV_DLY_ENC_OBS_SELECT_1 rw — Select value to map the addr bits delay observation registers to the accessible delay observation register for address slice 1.
  [2:0] PHY_ADR_SLAVE_LOOP_CNT_UPDATE_1 rw — Reserved for address slice 1.
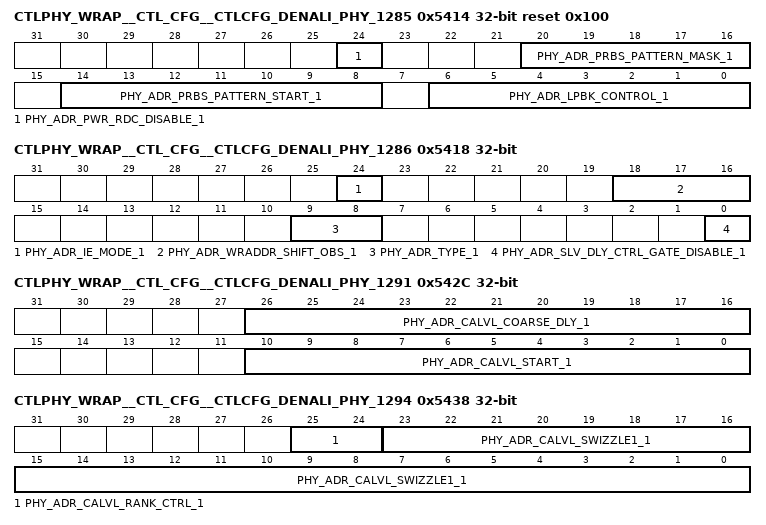
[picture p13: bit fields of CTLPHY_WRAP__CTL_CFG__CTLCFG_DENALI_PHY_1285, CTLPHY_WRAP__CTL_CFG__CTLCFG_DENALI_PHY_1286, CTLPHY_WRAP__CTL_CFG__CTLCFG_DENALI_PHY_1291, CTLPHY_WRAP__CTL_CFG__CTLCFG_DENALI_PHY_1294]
0x5414 CTLPHY_WRAP__CTL_CFG__CTLCFG_DENALI_PHY_1285 reset 0x100
  [24] PHY_ADR_PWR_RDC_DISABLE_1 — Power reduction disable for address slice 1.
  [20:16] PHY_ADR_PRBS_PATTERN_MASK_1 — PRBS7 mask signal for address slice 1.
  [14:8] PHY_ADR_PRBS_PATTERN_START_1 — PRBS7 start pattern for address slice 1.
  [6:0] PHY_ADR_LPBK_CONTROL_1 — Loopback control bits for address slice 1.
0x5418 CTLPHY_WRAP__CTL_CFG__CTLCFG_DENALI_PHY_1286 access per field
  [24] PHY_ADR_IE_MODE_1 rw — Input enable control for address slice 1.
  [18:16] PHY_ADR_WRADDR_SHIFT_OBS_1 ro — Observation register containing automatic half cycle and cycle shift values for address slice 1. READ-ONLY
  [9:8] PHY_ADR_TYPE_1 rw — DRAM type for address slice 1.
  [0] PHY_ADR_SLV_DLY_CTRL_GATE_DISABLE_1 rw — Power reduction slv_dly_control block gate disable for address slice 1.
0x541C CTLPHY_WRAP__CTL_CFG__CTLCFG_DENALI_PHY_1287
  [26:0] PHY_ADR_DDL_MODE_1 — DDL mode for address slice 1.
0x5420 CTLPHY_WRAP__CTL_CFG__CTLCFG_DENALI_PHY_1288
  [5:0] PHY_ADR_DDL_MASK_1 — DDL mask for address slice 1.
0x5424 CTLPHY_WRAP__CTL_CFG__CTLCFG_DENALI_PHY_1289 ro
  [31:0] PHY_ADR_DDL_TEST_OBS_1 — Observation register containing DDL test bits for address slice 1. READ-ONLY
0x5428 CTLPHY_WRAP__CTL_CFG__CTLCFG_DENALI_PHY_1290 ro
  [31:0] PHY_ADR_DDL_TEST_MSTR_DLY_OBS_1 — Observation register containing controller DDL bits for address slice 1. READ-ONLY
0x542C CTLPHY_WRAP__CTL_CFG__CTLCFG_DENALI_PHY_1291
  [26:16] PHY_ADR_CALVL_COARSE_DLY_1 — Coarse CA training DDL increment value for address slice 1.
  [10:0] PHY_ADR_CALVL_START_1 — CA training DDL start value for address slice 1.
0x5430 CTLPHY_WRAP__CTL_CFG__CTLCFG_DENALI_PHY_1292
  [10:0] PHY_ADR_CALVL_QTR_1 — CA training DDL quarter cycle delay value for address slice 1.
0x5434 CTLPHY_WRAP__CTL_CFG__CTLCFG_DENALI_PHY_1293
  [23:0] PHY_ADR_CALVL_SWIZZLE0_1 — CA training RD DQ bit swizzle map 0 for address slice 1.
0x5438 CTLPHY_WRAP__CTL_CFG__CTLCFG_DENALI_PHY_1294
  [25:24] PHY_ADR_CALVL_RANK_CTRL_1 — CA training rank aggregation control bits for address slice 1.
  [23:0] PHY_ADR_CALVL_SWIZZLE1_1 — CA training RD DQ bit swizzle map 1 for address slice 1.
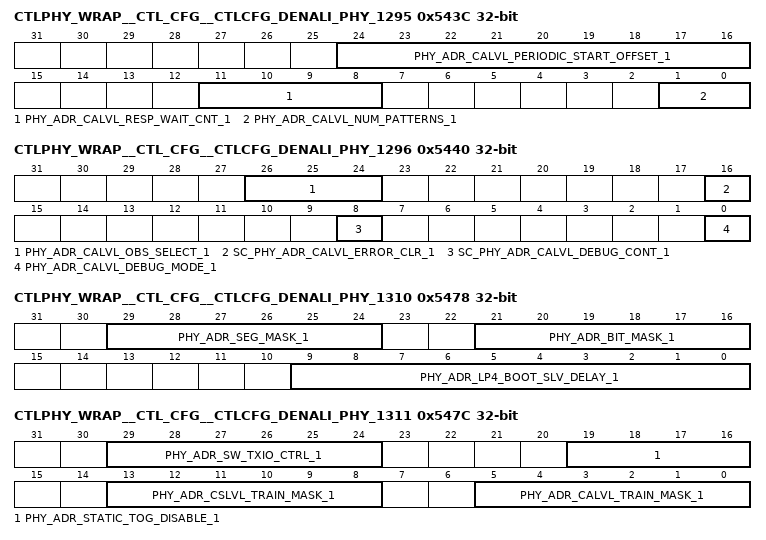
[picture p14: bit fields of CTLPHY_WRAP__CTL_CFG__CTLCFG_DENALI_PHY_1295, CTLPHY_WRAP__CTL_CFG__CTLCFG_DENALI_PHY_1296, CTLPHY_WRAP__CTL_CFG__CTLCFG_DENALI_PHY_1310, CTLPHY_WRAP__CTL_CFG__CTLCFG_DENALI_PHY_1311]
0x543C CTLPHY_WRAP__CTL_CFG__CTLCFG_DENALI_PHY_1295
  [24:16] PHY_ADR_CALVL_PERIODIC_START_OFFSET_1 — Relative offset to start periodic CALVL from previous result
  [11:8] PHY_ADR_CALVL_RESP_WAIT_CNT_1 — Number of samples to wait before sampling response during CA training for address slice 1.
  [1:0] PHY_ADR_CALVL_NUM_PATTERNS_1 — Number of patterns to use during CA training for address slice 1.
0x5440 CTLPHY_WRAP__CTL_CFG__CTLCFG_DENALI_PHY_1296 access per field
  [26:24] PHY_ADR_CALVL_OBS_SELECT_1 rw — CA bit lane to observe result from OBS0 during CA training for address slice 1.
  [16] SC_PHY_ADR_CALVL_ERROR_CLR_1 wo — Clears the CA training state machine error status for address slice 1. Set to 1 to trigger. WRITE-ONLY
  [8] SC_PHY_ADR_CALVL_DEBUG_CONT_1 wo — Allows the CA training state machine to advance [when in debug mode] for address slice 1. Set to 1 to trigger. WRITE-ONLY
  [0] PHY_ADR_CALVL_DEBUG_MODE_1 rw — Enables CA training debug mode for address slice 1. Set to 1 to enable.
0x5444 CTLPHY_WRAP__CTL_CFG__CTLCFG_DENALI_PHY_1297 ro
  [31:0] PHY_ADR_CALVL_CH0_OBS0_1 — Observation register for CA training for channel 0 slice 1. READ-ONLY
0x5448 CTLPHY_WRAP__CTL_CFG__CTLCFG_DENALI_PHY_1298 ro
  [31:0] PHY_ADR_CALVL_CH1_OBS0_1 — Observation register for CA training for channel 1 slice 1. READ-ONLY
0x544C CTLPHY_WRAP__CTL_CFG__CTLCFG_DENALI_PHY_1299 ro
  [31:0] PHY_ADR_CALVL_OBS1_1 — Observation register contains general CA training bits for slice 1. READ-ONLY
0x5450 CTLPHY_WRAP__CTL_CFG__CTLCFG_DENALI_PHY_1300 ro reset 0x100
  [31:0] PHY_ADR_CALVL_OBS2_1 — Observation register contains periodic CA training bits for slice 1. READ-ONLY
0x5454 CTLPHY_WRAP__CTL_CFG__CTLCFG_DENALI_PHY_1301
  [19:0] PHY_ADR_CALVL_FG_0_1 — CA training foreground pattern 0 for address slice 1.
0x5458 CTLPHY_WRAP__CTL_CFG__CTLCFG_DENALI_PHY_1302
  [19:0] PHY_ADR_CALVL_BG_0_1 — CA training background pattern 0 for address slice 1.
0x545C CTLPHY_WRAP__CTL_CFG__CTLCFG_DENALI_PHY_1303
  [19:0] PHY_ADR_CALVL_FG_1_1 — CA training foreground pattern 1 for address slice 1.
0x5460 CTLPHY_WRAP__CTL_CFG__CTLCFG_DENALI_PHY_1304
  [19:0] PHY_ADR_CALVL_BG_1_1 — CA training background pattern 1 for address slice 1.
0x5464 CTLPHY_WRAP__CTL_CFG__CTLCFG_DENALI_PHY_1305
  [19:0] PHY_ADR_CALVL_FG_2_1 — CA training foreground pattern 2 for address slice 1.
0x5468 CTLPHY_WRAP__CTL_CFG__CTLCFG_DENALI_PHY_1306
  [19:0] PHY_ADR_CALVL_BG_2_1 — CA training background pattern 2 for address slice 1.
0x546C CTLPHY_WRAP__CTL_CFG__CTLCFG_DENALI_PHY_1307
  [19:0] PHY_ADR_CALVL_FG_3_1 — CA training foreground pattern 3 for address slice 1.
0x5470 CTLPHY_WRAP__CTL_CFG__CTLCFG_DENALI_PHY_1308
  [19:0] PHY_ADR_CALVL_BG_3_1 — CA training background pattern 3 for address slice 1.
0x5474 CTLPHY_WRAP__CTL_CFG__CTLCFG_DENALI_PHY_1309
  [29:0] PHY_ADR_ADDR_SEL_1 — Selects which DFI address pins connect to which CA pins for LPDDR3/4 for address slice 1.
0x5478 CTLPHY_WRAP__CTL_CFG__CTLCFG_DENALI_PHY_1310
  [29:24] PHY_ADR_SEG_MASK_1 — Segment mask bit for address slice 1. Set to 1 to indicate that the bit is either CA 4 or CA 9.
  [21:16] PHY_ADR_BIT_MASK_1 — Mask bit for address slice 1. Set to 1 to indicate that the bit is used.
  [9:0] PHY_ADR_LP4_BOOT_SLV_DELAY_1 — Address target delay setting during the LPDDR4 boot frequency operation for address slice 1.
0x547C CTLPHY_WRAP__CTL_CFG__CTLCFG_DENALI_PHY_1311
  [29:24] PHY_ADR_SW_TXIO_CTRL_1 — Controls address pad output enable for address slice 1. Set to 1 to disable output enable.
  [19:16] PHY_ADR_STATIC_TOG_DISABLE_1 — Toggle control during static activity for address slice 1. Set bit to dsiable toggling, bit0: Write path delay line, bit1: Read path delay line, bit2: Read data path, bit3: clk_phy, bit4: controller delay line.
  [13:8] PHY_ADR_CSLVL_TRAIN_MASK_1 — Mask bit for CS training participation for address slice 1. Set to 1 to indicate that the bit is participating in CS training.
  [5:0] PHY_ADR_CALVL_TRAIN_MASK_1 — Mask bit for CA training participation for address slice 1. Set to 1 to indicate that the bit is participating in CA training.
0x5480 CTLPHY_WRAP__CTL_CFG__CTLCFG_DENALI_PHY_1312 reset 0x20202003
  [31:24] PHY_ADR_DC_ADR2_CLK_ADJUST_1 — Adjust value of Clock Duty Cycle Adjuster lane 2 for address slice 1.
  [23:16] PHY_ADR_DC_ADR1_CLK_ADJUST_1 — Adjust value of Clock Duty Cycle Adjuster lane 1 for address slice 1.
  [15:8] PHY_ADR_DC_ADR0_CLK_ADJUST_1 — Adjust value of Clock Duty Cycle Adjuster lane 0 for address slice 1.
  [1:0] PHY_ADR_DC_INIT_DISABLE_1 — Duty Cycle Corrector disable at initialization for address slice 1. Set to 1 to disable, bit [1] controls data path, bit [0] controls clock path.
0x5484 CTLPHY_WRAP__CTL_CFG__CTLCFG_DENALI_PHY_1313 reset 0x202020
  [24] PHY_ADR_DCC_RXCAL_CTRL_GATE_DISABLE_1 — DCC and RX_CAL clk gate disable for address slice 1. 1 = disable clk gate.
  [23:16] PHY_ADR_DC_ADR5_CLK_ADJUST_1 — Adjust value of Clock Duty Cycle Adjuster lane 5 for address slice 1.
  [15:8] PHY_ADR_DC_ADR4_CLK_ADJUST_1 — Adjust value of Clock Duty Cycle Adjuster lane 4 for address slice 1.
  [7:0] PHY_ADR_DC_ADR3_CLK_ADJUST_1 — Adjust value of Clock Duty Cycle Adjuster lane 3 for address slice 1.
0x5488 CTLPHY_WRAP__CTL_CFG__CTLCFG_DENALI_PHY_1314
  [29:24] PHY_ADR_DC_ADJUST_START_1 — DCC calibration starting value for address slice 1.
  [17:16] PHY_ADR_DC_WEIGHT_1 — DCC weighting factor base value for address slice 1.
  [15:8] PHY_ADR_DC_CAL_TIMEOUT_1 — DCC number of iterations to wait before timeout for address slice 1.
  [7:0] PHY_ADR_DC_CAL_SAMPLE_WAIT_1 — DCC cycles to wait after calibration change before sampling results for address slice 1.
0x548C CTLPHY_WRAP__CTL_CFG__CTLCFG_DENALI_PHY_1315
  [24] PHY_ADR_DC_CAL_POLARITY_1 — DCC calibration polarity for address slice 1.
  [16] PHY_ADR_DC_ADJUST_DIRECT_1 — DCC adjust direction for address slice 1.
  [15:8] PHY_ADR_DC_ADJUST_THRSHLD_1 — DCC adjust threshold around the mid-point for address slice 1.
  [7:0] PHY_ADR_DC_ADJUST_SAMPLE_CNT_1 — DCC number of samples to take for address slice 1.
0x5490 CTLPHY_WRAP__CTL_CFG__CTLCFG_DENALI_PHY_1316
  [13:8] PHY_ADR_SW_TXPWR_CTRL_1 — Disable address output enables in deep sleep mode for address slice 1.
  [0] PHY_ADR_DC_CAL_START_1 — DCC Manual trigger for address slice 1.
0x5494 CTLPHY_WRAP__CTL_CFG__CTLCFG_DENALI_PHY_1317
  [26:16] PHY_PAD_ADR_IO_CFG_1 — Controls I/O pads for address pad for address slice 1. Bits [10:5] = Park value, bits [4] park override, bits [2:0] clk divider.
  [10:8] PHY_ADR_DC_CAL_CLK_SEL_1 — DCC CAL clock for address slice 1.
  [7:0] PHY_ADR_TSEL_SELECT_1 — Tsel select values for address slice 1.
0x5498 CTLPHY_WRAP__CTL_CFG__CTLCFG_DENALI_PHY_1318
  [26:16] PHY_ADR0_CLK_WR_SLAVE_DELAY_1 — CA bit 0 target delay setting for address slice 1.
  [12:8] PHY_ADR0_SW_WRADDR_SHIFT_1 — Manual override of CA bit 0 of automatic half_cycle_shift/cycle_shift for address slice 1. Bit [0] enables override of half_cycle_shift. Bit [1] is the half_cycle_shift value. Bit [2] enables override of cycle shift. Bits [4:3] is the cycle_shift value. For bits [4:3], clear to 0x0 for no offset, program to 0x1 for -1 cycle, program to 0x2 for +1 cycle, or program to 0x3 for -2 cycles.
  [2:0] PHY_PAD_ADR_RX_PCLK_CLK_SEL_1 — Reserved for address slice 1.
0x549C CTLPHY_WRAP__CTL_CFG__CTLCFG_DENALI_PHY_1319
  [28:24] PHY_ADR2_SW_WRADDR_SHIFT_1 — Manual override of CA bit 2 of automatic half_cycle_shift/cycle_shift for address slice 1. Bit [0] enables override of half_cycle_shift. Bit [1] is the half_cycle_shift value. Bit [2] enables override of cycle shift. Bits [4:3] is the cycle_shift value. For bits [4:3], clear to 0x0 for no offset, program to 0x1 for -1 cycle, program to 0x2 for +1 cycle, or program to 0x3 for -2 cycles.
  [18:8] PHY_ADR1_CLK_WR_SLAVE_DELAY_1 — CA bit 1 target delay setting for address slice 1.
  [4:0] PHY_ADR1_SW_WRADDR_SHIFT_1 — Manual override of CA bit 1 of automatic half_cycle_shift/cycle_shift for address slice 1. Bit [0] enables override of half_cycle_shift. Bit [1] is the half_cycle_shift value. Bit [2] enables override of cycle shift. Bits [4:3] is the cycle_shift value. For bits [4:3], clear to 0x0 for no offset, program to 0x1 for -1 cycle, program to 0x2 for +1 cycle, or program to 0x3 for -2 cycles.
{0x4000+4i} CTLPHY_WRAP__CTL_CFG__CTLCFG_DENALI_PHY_{i} (i=1320..1322)
  [20:16] PHY_ADR{i-1317}_SW_WRADDR_SHIFT_1 — Manual override of CA bit {i-1317} of automatic half_cycle_shift/cycle_shift for address slice 1. Bit [0] enables override of half_cycle_shift. Bit [1] is the half_cycle_shift value. Bit [2] enables override of cycle shift. Bits [4:3] is the cycle_shift value. For bits [4:3], clear to 0x0 for no offset, program to 0x1 for -1 cycle, program to 0x2 for +1 cycle, or program to 0x3 for -2 cycles.
  [10:0] PHY_ADR{i-1318}_CLK_WR_SLAVE_DELAY_1 — CA bit {i-1318} target delay setting for address slice 1.
0x54AC CTLPHY_WRAP__CTL_CFG__CTLCFG_DENALI_PHY_1323
  [19:16] PHY_ADR_SW_MASTER_MODE_1 — Controller delay line override settings for address slice 1. Bit [0] enables software half clock mode. Bit [1] is the software half clock mode value. Bit [2] enables software bypass mode. Bit [3] is the software bypass mode value.
  [10:0] PHY_ADR5_CLK_WR_SLAVE_DELAY_1 — CA bit 5 target delay setting for address slice 1.
0x54B0 CTLPHY_WRAP__CTL_CFG__CTLCFG_DENALI_PHY_1324
  [31:24] PHY_ADR_MASTER_DELAY_WAIT_1 — Wait cycles for controller delay line locking algorithm for address slice 1. Bits [3:0] is the cycle wait count after a calibration clock setting change. Bits [7:4] is the cycle wait count after a controller delay setting change.
  [21:16] PHY_ADR_MASTER_DELAY_STEP_1 — Incremental step size for controller delay line locking algorithm for address slice 1.
  [10:0] PHY_ADR_MASTER_DELAY_START_1 — Start value for controller delay line locking algorithm for address slice 1.
0x54B4 CTLPHY_WRAP__CTL_CFG__CTLCFG_DENALI_PHY_1325
  [24] PHY_ADR_SW_CALVL_DVW_MIN_EN_1 — Enables the software override data valid window size during CA training for address slice 1.
  [17:8] PHY_ADR_SW_CALVL_DVW_MIN_1 — Sets the software override data valid window size during CA training for address slice 1.
  [7:0] PHY_ADR_MASTER_DELAY_HALF_MEASURE_1 — Defines the number of delay line elements to be considered in determing whether to lock to a half clock cycle for the controller in address slice 1
0x54B8 CTLPHY_WRAP__CTL_CFG__CTLCFG_DENALI_PHY_1326
  [3:0] PHY_ADR_CALVL_DLY_STEP_1 — Sets the delay step size plus 1 during CA training for address slice 1.
0x54BC CTLPHY_WRAP__CTL_CFG__CTLCFG_DENALI_PHY_1327
  [25:16] PHY_ADR_DC_INIT_SLV_DELAY_1 — DCC initialization value of write ADDR target delay for address slice 1.
  [8] PHY_ADR_MEAS_DLY_STEP_ENABLE_1 — Enables delay parameter setting using phy_adr_meas_dly_step_value for address slice 1.
  [3:0] PHY_ADR_CALVL_CAPTURE_CNT_1 — Number of samples to take at each ADDR target delay setting during CA training for address slice 1.
0x54C0 CTLPHY_WRAP__CTL_CFG__CTLCFG_DENALI_PHY_1328
  [15:8] PHY_ADR_DC_DM_CLK_THRSHLD_1 — DCC clock measurement cell threshold offset for address slice 1.
  [0] PHY_ADR_DC_CALVL_ENABLE_1 — DCC enable duty cycle adjust during CA leveling for address slice 1.
0x5800 CTLPHY_WRAP__CTL_CFG__CTLCFG_DENALI_PHY_1536 access per field
  [26:24] SC_PHY_ADR_MANUAL_CLEAR_2 wo — Manual reset/clear of internal logic for address slice 2. Bit [0] is reset of controller delay min/max lock values. Bit [1] is manual reset of controller delay unlock counter. Bit [2] clears the loopback error/results registers. Set each bit to 1 to reset. WRITE-ONLY
  [16] PHY_ADR_CLK_BYPASS_OVERRIDE_2 rw — Bypass mode override setting for address slice 2. Set to 1 to enable.
  [10:0] PHY_ADR_CLK_WR_BYPASS_SLAVE_DELAY_2 rw — Command/Address clock bypass mode target delay setting for address slice 2.
0x5804 CTLPHY_WRAP__CTL_CFG__CTLCFG_DENALI_PHY_1537 ro reset 0x1000
  [31:0] PHY_ADR_LPBK_RESULT_OBS_2 — Observation register containing loopback status/results for address slice 2. READ-ONLY
0x5808 CTLPHY_WRAP__CTL_CFG__CTLCFG_DENALI_PHY_1538 access per field
  [27:24] PHY_ADR_MASTER_DLY_LOCK_OBS_SELECT_2 rw — Select value to map the internal controller delay observation registers to the accessible controller delay observation register for address slice 2.
  [23:16] PHY_ADR_MEAS_DLY_STEP_VALUE_2 ro — Contains the fraction of a cycle in 1 delay element numerator with demominator of 512, for address slice 2. READ-ONLY
  [15:0] PHY_ADR_LPBK_ERROR_COUNT_OBS_2 ro — Observation register containing total number of loopback error data for address slice 2. READ-ONLY
0x580C CTLPHY_WRAP__CTL_CFG__CTLCFG_DENALI_PHY_1539 ro
  [31:24] PHY_ADR_ADDER_SLV_DLY_ENC_OBS_2 — Observation register containing addr target delay for address slice 2. READ-ONLY
  [22:16] PHY_ADR_BASE_SLV_DLY_ENC_OBS_2 — Observation register containing base target delay for address slice 2. READ-ONLY
  [10:0] PHY_ADR_MASTER_DLY_LOCK_OBS_2 — Observation register containing controller delay results for address slice 2. READ-ONLY
0x5810 CTLPHY_WRAP__CTL_CFG__CTLCFG_DENALI_PHY_1540 access per field
  [24] PHY_ADR_TSEL_ENABLE_2 rw — Enables tsel_en for address slice 2.
  [16] SC_PHY_ADR_SNAP_OBS_REGS_2 wo — Initiates a snapshot of the internal observation registers for address slice 2. Set to 1 to trigger. WRITE-ONLY
  [10:8] PHY_ADR_SLV_DLY_ENC_OBS_SELECT_2 rw — Select value to map the addr bits delay observation registers to the accessible delay observation register for address slice 2.
  [2:0] PHY_ADR_SLAVE_LOOP_CNT_UPDATE_2 rw — Reserved for address slice 2.
0x5814 CTLPHY_WRAP__CTL_CFG__CTLCFG_DENALI_PHY_1541 reset 0x100
  [24] PHY_ADR_PWR_RDC_DISABLE_2 — Power reduction disable for address slice 2.
  [20:16] PHY_ADR_PRBS_PATTERN_MASK_2 — PRBS7 mask signal for address slice 2.
  [14:8] PHY_ADR_PRBS_PATTERN_START_2 — PRBS7 start pattern for address slice 2.
  [6:0] PHY_ADR_LPBK_CONTROL_2 — Loopback control bits for address slice 2.
0x5818 CTLPHY_WRAP__CTL_CFG__CTLCFG_DENALI_PHY_1542 access per field
  [24] PHY_ADR_IE_MODE_2 rw — Input enable control for address slice 2.
  [18:16] PHY_ADR_WRADDR_SHIFT_OBS_2 ro — Observation register containing automatic half cycle and cycle shift values for address slice 2. READ-ONLY
  [9:8] PHY_ADR_TYPE_2 rw — DRAM type for address slice 2.
  [0] PHY_ADR_SLV_DLY_CTRL_GATE_DISABLE_2 rw — Power reduction slv_dly_control block gate disable for address slice 2.
0x581C CTLPHY_WRAP__CTL_CFG__CTLCFG_DENALI_PHY_1543
  [26:0] PHY_ADR_DDL_MODE_2 — DDL mode for address slice 2.
0x5820 CTLPHY_WRAP__CTL_CFG__CTLCFG_DENALI_PHY_1544
  [5:0] PHY_ADR_DDL_MASK_2 — DDL mask for address slice 2.
0x5824 CTLPHY_WRAP__CTL_CFG__CTLCFG_DENALI_PHY_1545 ro
  [31:0] PHY_ADR_DDL_TEST_OBS_2 — Observation register containing DDL test bits for address slice 2. READ-ONLY
0x5828 CTLPHY_WRAP__CTL_CFG__CTLCFG_DENALI_PHY_1546 ro
  [31:0] PHY_ADR_DDL_TEST_MSTR_DLY_OBS_2 — Observation register containing controller DDL bits for address slice 2. READ-ONLY
0x582C CTLPHY_WRAP__CTL_CFG__CTLCFG_DENALI_PHY_1547
  [26:16] PHY_ADR_CALVL_COARSE_DLY_2 — Coarse CA training DDL increment value for address slice 2.
  [10:0] PHY_ADR_CALVL_START_2 — CA training DDL start value for address slice 2.
0x5830 CTLPHY_WRAP__CTL_CFG__CTLCFG_DENALI_PHY_1548
  [10:0] PHY_ADR_CALVL_QTR_2 — CA training DDL quarter cycle delay value for address slice 2.
0x5834 CTLPHY_WRAP__CTL_CFG__CTLCFG_DENALI_PHY_1549
  [23:0] PHY_ADR_CALVL_SWIZZLE0_2 — CA training RD DQ bit swizzle map 0 for address slice 2.
